# MCU_CPSW0_NUSS_CPINT register map
Vendor: Texas Instruments
Peripheral module from a debugger description file (folder am65x).
Registers are 32-bit, access not given, reset values left out (the file's numbers can be read two ways) unless marked. A register's access mark holds for its fields unless they carry their own. Offsets are as the file gives them; lines under a group give offsets from that group; [hi:lo] are bit positions; {n}, {i} and the like mark numbered series; 'fields as' and 'values as' point back to an identical list; <NAME> marks a mode.

## MCU_CPSW0_NUSS_CPINT
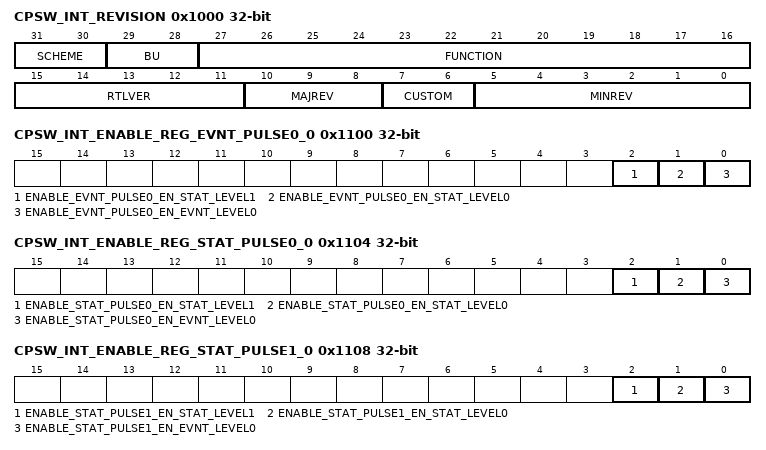
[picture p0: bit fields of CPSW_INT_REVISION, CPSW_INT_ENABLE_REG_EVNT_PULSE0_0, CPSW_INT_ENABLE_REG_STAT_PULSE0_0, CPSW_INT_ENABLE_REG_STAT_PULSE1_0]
0x1000 CPSW_INT_REVISION ro — Revision Register
  [31:30] SCHEME
  [29:28] BU
  [27:16] FUNCTION — Module ID
  [15:11] RTLVER — RTL revisions
  [10:8] MAJREV — Major
  [7:6] CUSTOM
  [5:0] MINREV — Minor
0x1004 CPSW_INT_CONTROL size not given — Register
0x1010 CPSW_INT_EOI_REG rw — End of Interrupt Register The EOI register is used to re-trigger the pulse interrupt signal to ensure that any nested interrupt events are serviced. The software interrupt handler must write to the EOI register at the end of the current interrupt processing routine, so that new events can re-trigger the pulse interrupt signal again. For level interrupt signals the EOI register is not functional and must not be used.
  [7:0] EOI_VECTOR — End of Interrupt Vector.
0x1014 CPSW_INT_INTR_VECTOR_REG ro — Interrupt Vector Register
  [31:0] INTR_VECTOR
0x1100 CPSW_INT_ENABLE_REG_EVNT_PULSE0_0 — Enable Register 0
  [2] ENABLE_EVNT_PULSE0_EN_STAT_LEVEL1 — Enable Set for evnt_pulse0_en_stat_level1 (access RW1S)
  [1] ENABLE_EVNT_PULSE0_EN_STAT_LEVEL0 — Enable Set for evnt_pulse0_en_stat_level0 (access RW1S)
  [0] ENABLE_EVNT_PULSE0_EN_EVNT_LEVEL0 — Enable Set for evnt_pulse0_en_evnt_level0 (access RW1S)
0x1104 CPSW_INT_ENABLE_REG_STAT_PULSE0_0 — Enable Register 1
  [2] ENABLE_STAT_PULSE0_EN_STAT_LEVEL1 — Enable Set for stat_pulse0_en_stat_level1 (access RW1S)
  [1] ENABLE_STAT_PULSE0_EN_STAT_LEVEL0 — Enable Set for stat_pulse0_en_stat_level0 (access RW1S)
  [0] ENABLE_STAT_PULSE0_EN_EVNT_LEVEL0 — Enable Set for stat_pulse0_en_evnt_level0 (access RW1S)
0x1108 CPSW_INT_ENABLE_REG_STAT_PULSE1_0 — Enable Register 2
  [2] ENABLE_STAT_PULSE1_EN_STAT_LEVEL1 — Enable Set for stat_pulse1_en_stat_level1 (access RW1S)
  [1] ENABLE_STAT_PULSE1_EN_STAT_LEVEL0 — Enable Set for stat_pulse1_en_stat_level0 (access RW1S)
  [0] ENABLE_STAT_PULSE1_EN_EVNT_LEVEL0 — Enable Set for stat_pulse1_en_evnt_level0 (access RW1S)
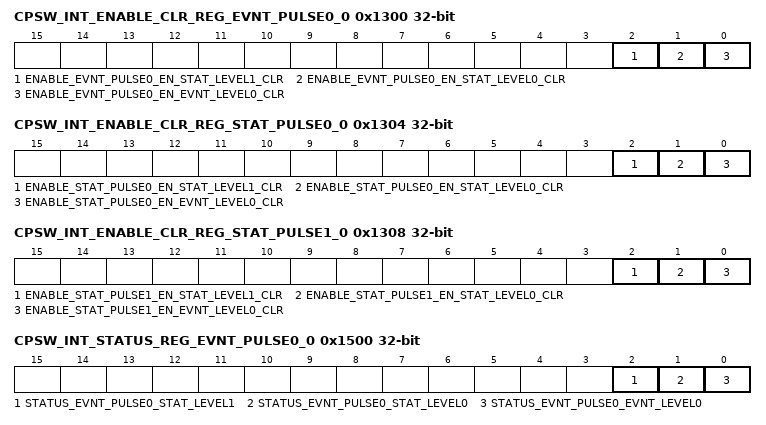
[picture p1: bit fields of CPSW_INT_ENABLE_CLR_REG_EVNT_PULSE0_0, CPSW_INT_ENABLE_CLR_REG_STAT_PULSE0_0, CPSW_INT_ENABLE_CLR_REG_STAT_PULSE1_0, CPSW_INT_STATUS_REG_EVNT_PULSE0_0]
0x1300 CPSW_INT_ENABLE_CLR_REG_EVNT_PULSE0_0 — Enable Clear Register 0
  [2] ENABLE_EVNT_PULSE0_EN_STAT_LEVEL1_CLR — Enable Clear for evnt_pulse0_en_stat_level1 (access RW1C)
  [1] ENABLE_EVNT_PULSE0_EN_STAT_LEVEL0_CLR — Enable Clear for evnt_pulse0_en_stat_level0 (access RW1C)
  [0] ENABLE_EVNT_PULSE0_EN_EVNT_LEVEL0_CLR — Enable Clear for evnt_pulse0_en_evnt_level0 (access RW1C)
0x1304 CPSW_INT_ENABLE_CLR_REG_STAT_PULSE0_0 — Enable Clear Register 1
  [2] ENABLE_STAT_PULSE0_EN_STAT_LEVEL1_CLR — Enable Clear for stat_pulse0_en_stat_level1 (access RW1C)
  [1] ENABLE_STAT_PULSE0_EN_STAT_LEVEL0_CLR — Enable Clear for stat_pulse0_en_stat_level0 (access RW1C)
  [0] ENABLE_STAT_PULSE0_EN_EVNT_LEVEL0_CLR — Enable Clear for stat_pulse0_en_evnt_level0 (access RW1C)
0x1308 CPSW_INT_ENABLE_CLR_REG_STAT_PULSE1_0 — Enable Clear Register 2
  [2] ENABLE_STAT_PULSE1_EN_STAT_LEVEL1_CLR — Enable Clear for stat_pulse1_en_stat_level1 (access RW1C)
  [1] ENABLE_STAT_PULSE1_EN_STAT_LEVEL0_CLR — Enable Clear for stat_pulse1_en_stat_level0 (access RW1C)
  [0] ENABLE_STAT_PULSE1_EN_EVNT_LEVEL0_CLR — Enable Clear for stat_pulse1_en_evnt_level0 (access RW1C)
0x1500 CPSW_INT_STATUS_REG_EVNT_PULSE0_0 ro — Status Register 0
  [2] STATUS_EVNT_PULSE0_STAT_LEVEL1 — Status for evnt_pulse0_en_stat_level1
  [1] STATUS_EVNT_PULSE0_STAT_LEVEL0 — Status for evnt_pulse0_en_stat_level0
  [0] STATUS_EVNT_PULSE0_EVNT_LEVEL0 — Status for evnt_pulse0_en_evnt_level0
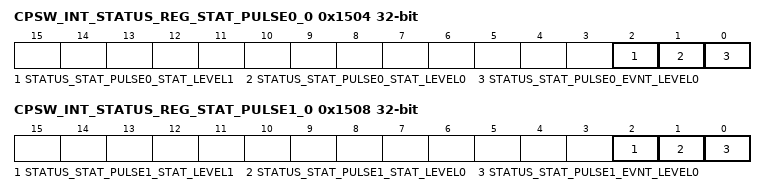
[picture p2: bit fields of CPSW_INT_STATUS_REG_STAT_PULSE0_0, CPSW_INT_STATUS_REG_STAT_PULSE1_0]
0x1504 CPSW_INT_STATUS_REG_STAT_PULSE0_0 ro — Status Register 1
  [2] STATUS_STAT_PULSE0_STAT_LEVEL1 — Status for stat_pulse0_en_stat_level1
  [1] STATUS_STAT_PULSE0_STAT_LEVEL0 — Status for stat_pulse0_en_stat_level0
  [0] STATUS_STAT_PULSE0_EVNT_LEVEL0 — Status for stat_pulse0_en_evnt_level0
0x1508 CPSW_INT_STATUS_REG_STAT_PULSE1_0 ro — Status Register 2
  [2] STATUS_STAT_PULSE1_STAT_LEVEL1 — Status for stat_pulse1_en_stat_level1
  [1] STATUS_STAT_PULSE1_STAT_LEVEL0 — Status for stat_pulse1_en_stat_level0
  [0] STATUS_STAT_PULSE1_EVNT_LEVEL0 — Status for stat_pulse1_en_evnt_level0
0x1700 CPSW_INT_STATUS_CLR_REG_EVNT_PULSE0_0 size not given — Status Clear Register 0
0x1704 CPSW_INT_STATUS_CLR_REG_STAT_PULSE0_0 size not given — Status Clear Register 1
0x1708 CPSW_INT_STATUS_CLR_REG_STAT_PULSE1_0 size not given — Status Clear Register 2
0x1A80 CPSW_INT_INTR_VECTOR_REG_EVNT_PULSE0 ro — Interrupt Vector for evnt_pulse0
  [31:0] INTR_VECTOR_EVNT_PULSE0 — Interrupt Vector
0x1A84 CPSW_INT_INTR_VECTOR_REG_STAT_PULSE0 ro — Interrupt Vector for stat_pulse0
  [31:0] INTR_VECTOR_STAT_PULSE0 — Interrupt Vector
0x1A88 CPSW_INT_INTR_VECTOR_REG_STAT_PULSE1 ro — Interrupt Vector for stat_pulse1
  [31:0] INTR_VECTOR_STAT_PULSE1 — Interrupt Vector
